# RA4M1 register map
Vendor: Renesas Electronics Corporation; Series: RA4; File version: 1.2
CPU: CM4 r0p1, little endian, MPU, FPU, VTOR, 4 interrupt priority bits
Registers are 8-bit, read-write, reset 0x0 unless marked. A register's access mark holds for its fields unless they carry their own. Offsets are from the block's base; [hi:lo] are bit positions.

## DBG — Debug Function
Base 0x4001B000
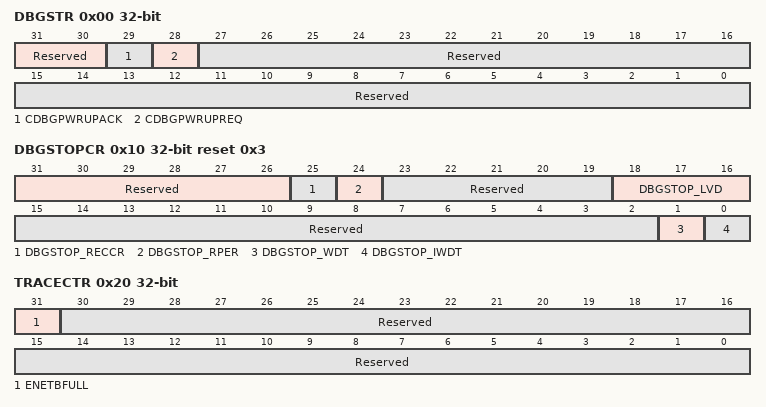
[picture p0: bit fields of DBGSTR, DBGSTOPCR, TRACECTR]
0x00 DBGSTR 32-bit ro — Debug Status Register
  [31:30] Reserved — These bits are read as 00.
  [29] CDBGPWRUPACK — Debug power-up acknowledge
    0=Debug power-up request is not acknowledged; 1=Debug power-up request is acknowledged
  [28] CDBGPWRUPREQ — Debug power-up request
    0=OCD is not requesting debug power-up; 1=OCD is requesting debug power-up
  [27:0] Reserved — These bits are read as 0000000000000000000000000000.
0x10 DBGSTOPCR 32-bit reset 0x3 — Debug Stop Control Register
  [31:26] Reserved — These bits are read as 000000. The write value should be 000000.
  [25] DBGSTOP_RECCR — Mask bit for RAM ECC error reset/interrupt
    0=Enable RAM ECC error reset/interrupt; 1=Mask RAM ECC error reset/interrupt
  [24] DBGSTOP_RPER — Mask bit for RAM parity error reset/interrupt
    0=Enable RAM parity error reset/interrupt; 1=Mask RAM parity error reset/interrupt
  [23:19] Reserved — These bits are read as 00000. The write value should be 00000.
  [18:16] DBGSTOP_LVD — b18: Mask bit for LVD2 reset/interrupt (0:enable / 1:Mask) b17: Mask bit for LVD1 reset/interrupt (0:enable / 1:Mask) b16: Mask bit for LVD0 reset (0:enable / 1:Mask)
  [15:2] Reserved — These bits are read as 00000000000000. The write value should be 00000000000000.
  [1] DBGSTOP_WDT — Mask bit for WDT reset/interrupt
    0=Mask WDT reset/interrupt; 1=Enable WDT reset
  [0] DBGSTOP_IWDT — Mask bit for IWDT reset/interrupt
    0=Mask IWDT reset/interrupt; 1=Enable IWDT reset
0x20 TRACECTR 32-bit — Trace Control Register
  [31] ENETBFULL — Enable bit for halt request by ETB full
    0=ETB full does not cause CPU halt; 1=ETB full cause CPU halt
  [30:0] Reserved — These bits are read as 0000000000000000000000000000000. The write value should be 0000000000000000000000000000000.

## CRC — CRC Calculator
Base 0x40074000
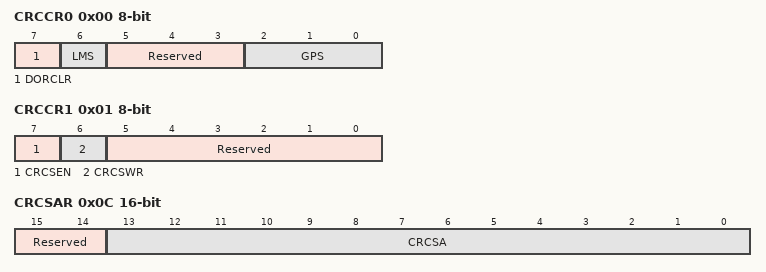
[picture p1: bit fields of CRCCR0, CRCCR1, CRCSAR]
0x00 CRCCR0 — CRC Control Register0
  [7] DORCLR wo — CRCDOR Register Clear
    0=No effect; 1=Clears the CRCDOR register
  [6] LMS — CRC Calculation Switching
    0=Generates CRC for LSB first communication; 1=Generates CRC for MSB first communication
  [5:3] Reserved — These bits are read as 000. The write value should be 000.
  [2:0] GPS — CRC Generating Polynomial Switching
    0=No calculation is executed; 1=8-bit CRC-8 (X8 + X2 + X + 1); 2=16-bit CRC-16 (X16 + X15 + X2 + 1); 3=16-bit CRC-CCITT (X16 + X12 + X5 + 1); 4=32-bit CRC-32 (X32+X26+X23+X22+X16+X12+X11+X10+X8+X7+X5+X4+X2+X+1); 5=32-bit CRC-32C (X32+X28+X27+X26+ X25+X23+X22+X20+X19+X18+X14+X13+X11+X10+X9+X8+X6+1); other=others (No calculation is executed.)
0x01 CRCCR1 — CRC Control Register1
  [7] CRCSEN — Snoop enable bit
    0=Disabled; 1=Enabled
  [6] CRCSWR — Snoop-on-write/read switch bit
    0=Snoop-on-read; 1=Snoop-on-write
  [5:0] Reserved — These bits are read as 000000. The write value should be 000000.
0x04 CRCDIR 32-bit — CRC Data Input Register
  [31:0] CRCDIR — Calculation input Data (Case of CRC-32, CRC-32C )
0x04 CRCDIR_BY (alternate view of CRCDIR) — CRC Data Input Register (byte access)
  [7:0] CRCDIR_BY — Calculation input Data ( Case of CRC-8, CRC-16 or CRC-CCITT )
0x08 CRCDOR 32-bit — CRC Data Output Register
  [31:0] CRCDOR — Calculation output Data (Case of CRC-32, CRC-32C )
0x08 CRCDOR_HA 16-bit (alternate view of CRCDOR) — CRC Data Output Register (halfword access)
  [15:0] CRCDOR_HA — Calculation output Data (Case of CRC-16 or CRC-CCITT )
0x08 CRCDOR_BY (alternate view of CRCDOR) — CRC Data Output Register(byte access)
  [7:0] CRCDOR_BY — Calculation output Data (Case of CRC-8 )
0x0C CRCSAR 16-bit — Snoop Address Register
  [15:14] Reserved — These bits are read as 00. The write value should be 00.
  [13:0] CRCSA — snoop address bit Set the I/O register address to snoop
    3=SCI0.TDR; 5=SCI0.RDR; 35=SCI1.TDR; 37=SCI1.RDR; 67=SCI2.TDR; 69=SCI2.RDR; 99=SCI3.TDR; 101=SCI3.RDR; 131=SCI4.TDR; 133=SCI4.RDR; 0x123=SCI9.TDR; 0x125=SCI9.RDR; other=others (Settings other than above are prohibited.)
